# AT90USB162 device description
Architecture: AVR8; Family: megaAVR
Programming and debug interfaces: ISP, HVPP, debugWIRE
Registers are 8-bit, access not given, no defined reset value unless marked. A register's access mark holds for its fields unless they carry their own. Offsets are from the block's base; lines under a group give offsets from that group; [hi:lo] are bit positions; {n}, {i} and the like mark numbered series; 'fields as' and 'values as' point back to an identical list; <NAME> marks a mode.

## Ordering variants
standard: 2.7 to 5.5 V

## Memory
prog space: start 0x0000 size 0x4000, little endian
  0x0000 FLASH size 0x4000 flash, rw, executable, page 0x80
  0x3e00 BOOT_SECTION_1 size 0x0200 flash, rw, executable, page 0x80
  0x3c00 BOOT_SECTION_2 size 0x0400 flash, rw, executable, page 0x80
  0x3800 BOOT_SECTION_3 size 0x0800 flash, rw, executable, page 0x80
  0x3000 BOOT_SECTION_4 size 0x1000 flash, rw, executable, page 0x80
signatures space: start 0 size 3, little endian
  0 SIGNATURES size 3 signatures, ro
fuses space: start 0 size 0x0003, little endian
  0 FUSES size 0x0003 fuses, rw
lockbits space: start 0 size 0x0001, little endian
  0 LOCKBITS size 0x0001 lockbits, rw
data space: start 0x0000 size 0x0300, little endian
  0x0000 REGISTERS size 0x0020 regs
  0x0020 MAPPED_IO size 0x00e0 io
  0x0100 IRAM size 0x0200 ram
eeprom space: start 0x0000 size 0x0200, little endian
  0x0000 EEPROM size 0x0200 eeprom, rw, page 0x04
io space: start 0x00 size 0x40, little endian
osccal space: start 0 size 1, little endian
  0 OSCCAL size 1 osccal, ro

## Peripheral instances (address, pins/pin function, parameters)
PORTB at 0x00 — I/O Port
PORTD at 0x00 — I/O Port
PORTC at 0x00 — I/O Port
SPI at 0x00 — Serial Peripheral Interface
BOOT_LOAD at 0x00 — Bootloader
EEPROM at 0x00
TC0 at 0x00 — Timer/Counter, 8-bit
TC1 at 0x00 — Timer/Counter, 16-bit
PLL at 0x00 — Phase Locked Loop
USB_DEVICE at 0x00 — USB Device Registers
PS2 at 0x00 — PS/2 Controller
CPU at 0x00 — CPU Registers
  parameters: CORE_VERSION=V2
EXINT at 0x00 — External Interrupts
USART1 at 0x00 — USART
WDT at 0x00 — Watchdog Timer
AC at 0x00 — Analog Comparator
FUSE at 0 in fuses — Fuses
LOCKBIT at 0 in lockbits — Lockbits

## Interrupts
0 RESET — External Pin,Power-on Reset,Brown-out Reset,Watchdog Reset,and JTAG AVR Reset. See Datasheet.
{n+1} INT{n} (n=0..7) — External Interrupt Request {n}
9 PCINT0 — Pin Change Interrupt Request 0
10 PCINT1 — Pin Change Interrupt Request 1
11 USB_GEN — USB General Interrupt Request
12 USB_COM — USB Endpoint/Pipe Interrupt Communication Request
13 WDT — Watchdog Time-out Interrupt
14 TIMER1_CAPT — Timer/Counter2 Capture Event
15 TIMER1_COMPA — Timer/Counter2 Compare Match B
16 TIMER1_COMPB — Timer/Counter2 Compare Match B
17 TIMER1_COMPC — Timer/Counter2 Compare Match C
18 TIMER1_OVF — Timer/Counter1 Overflow
19 TIMER0_COMPA — Timer/Counter0 Compare Match A
20 TIMER0_COMPB — Timer/Counter0 Compare Match B
21 TIMER0_OVF — Timer/Counter0 Overflow
22 SPI_STC — SPI Serial Transfer Complete
23 USART1_RX — USART1, Rx Complete
24 USART1_UDRE — USART1 Data register Empty
25 USART1_TX — USART1, Tx Complete
26 ANALOG_COMP — Analog Comparator
27 EE_READY — EEPROM Ready
28 SPM_READY — Store Program Memory Read

## Properties
SIGNATURES: JTAGID=0x9482, SIGNATURE0=0x1e, SIGNATURE1=0x94, SIGNATURE2=0x82
OCD: OCD_REVISION=1, OCD_DATAREG=0x31, PROGBASE=0x0000

## LOCKBIT — Lockbits
Instances: LOCKBIT 0 in lockbits
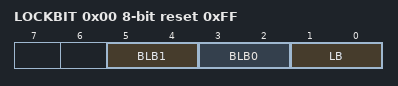
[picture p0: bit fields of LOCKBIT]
0x00 LOCKBIT reset 0xFF
  [5:4] BLB1 — Boot Loader Protection Mode
    0=LPM_SPM_DISABLE (LPM and SPM prohibited in Boot Section); 1=LPM_DISABLE (LPM prohibited in Boot Section); 2=SPM_DISABLE (SPM prohibited in Boot Section); 3=NO_LOCK (No lock on SPM and LPM in Boot Section)
  [3:2] BLB0 — Boot Loader Protection Mode
    0=LPM_SPM_DISABLE (LPM and SPM prohibited in Application Section); 1=LPM_DISABLE (LPM prohibited in Application Section); 2=SPM_DISABLE (SPM prohibited in Application Section); 3=NO_LOCK (No lock on SPM and LPM in Application Section)
  [1:0] LB — Memory Lock
    0=PROG_VER_DISABLED (Further programming and verification disabled); 2=PROG_DISABLED (Further programming disabled); 3=NO_LOCK (No memory lock features enabled)
